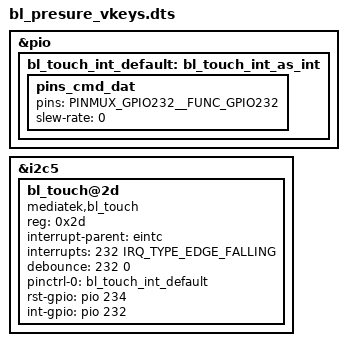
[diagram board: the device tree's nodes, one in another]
&pio{
	bl_touch_int_default:bl_touch_int_as_int{
		pins_cmd_dat {
			pins = <PINMUX_GPIO232__FUNC_GPIO232>;
			slew-rate = <0>;
		};
	};
};

&i2c5 {
	bl_touch@2d {
		compatible = "mediatek,bl_touch";
		reg = <0x2d>;
		interrupt-parent = <&eintc>;
		interrupts = <232 IRQ_TYPE_EDGE_FALLING>;
		debounce = <232 0>;
		pinctrl-names = "bl_touch_int";
		pinctrl-0 = <&bl_touch_int_default>;
		rst-gpio = <&pio 234 0>;
		int-gpio = <&pio 232 0>;
		status = "okay";
	};
};
